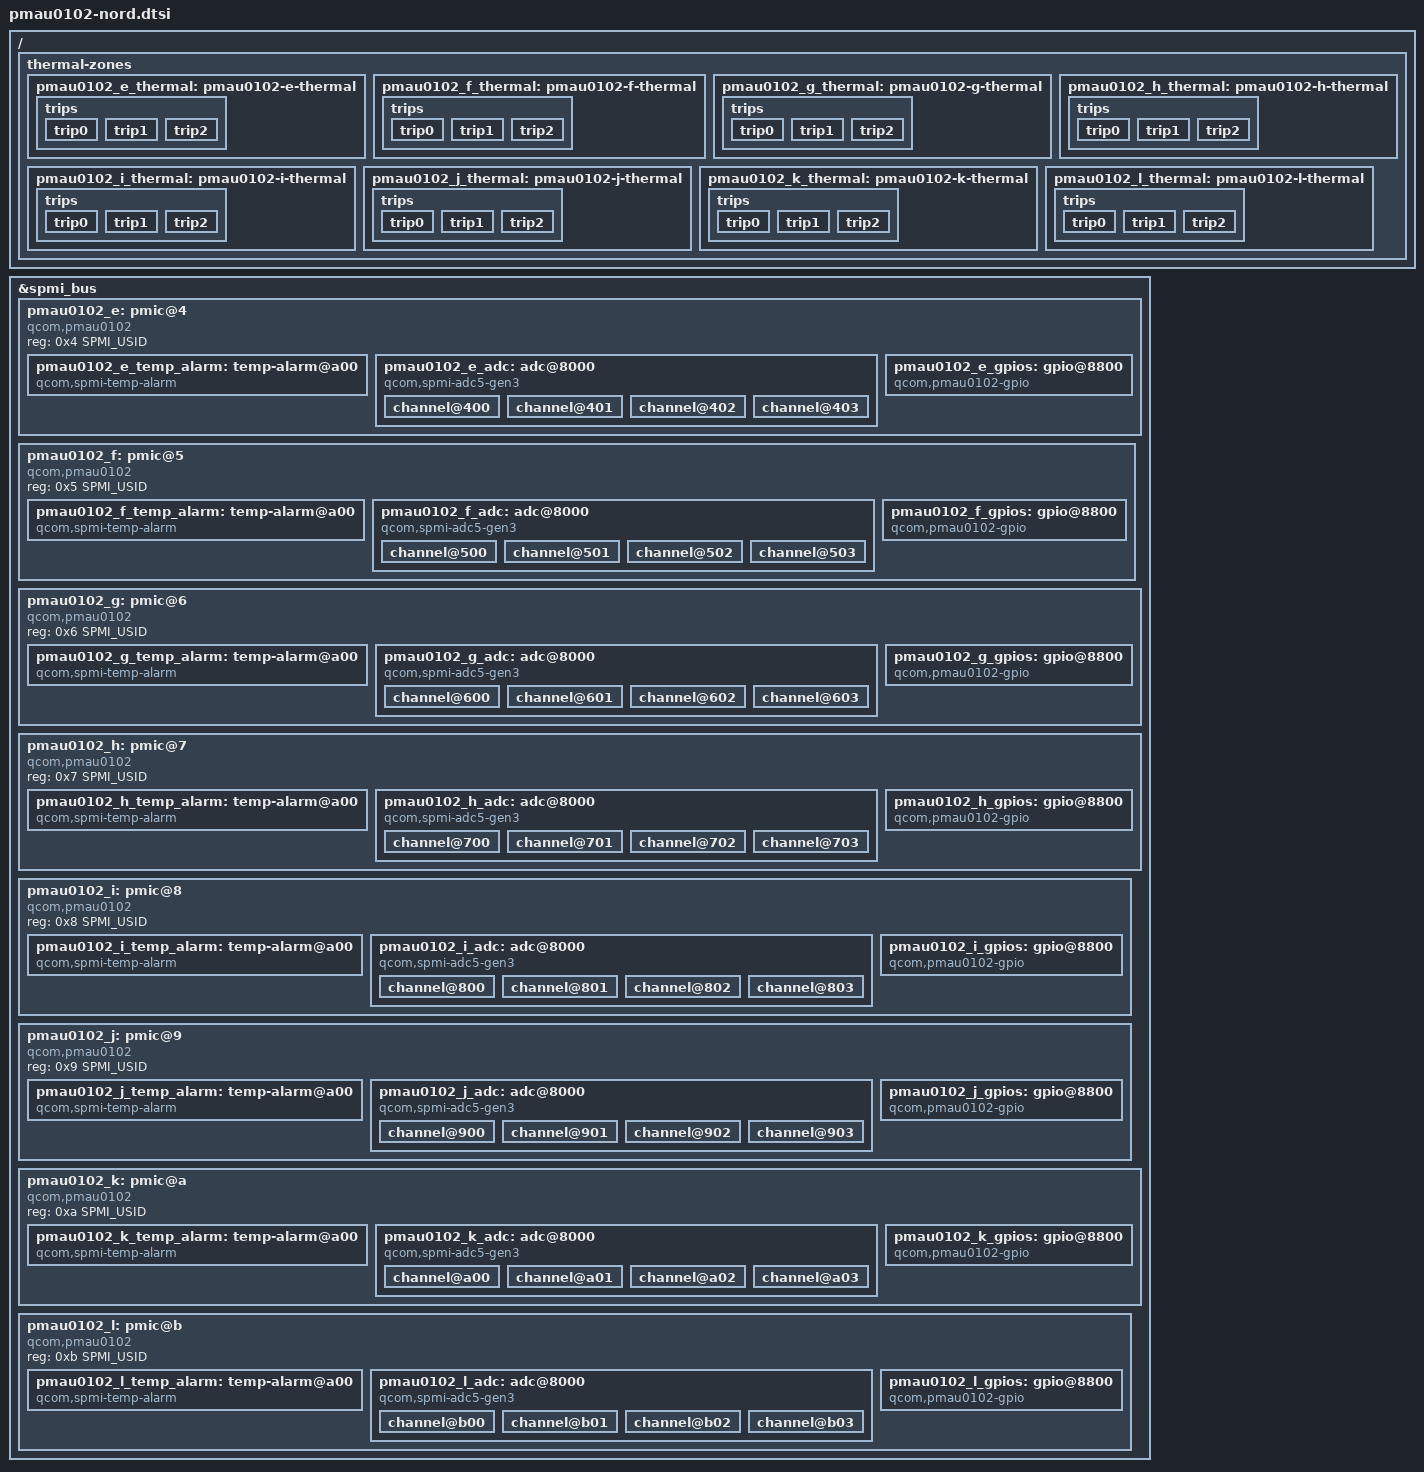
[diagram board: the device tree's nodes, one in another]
// SPDX-License-Identifier: BSD-3-Clause
/*
 * Copyright (c) Qualcomm Technologies, Inc. and/or its subsidiaries.
 */

#include <dt-bindings/interrupt-controller/irq.h>
#include <dt-bindings/spmi/spmi.h>
#include "qcom-adc5-gen3.h"

&spmi_bus {
	pmau0102_e: pmic@4 {
		compatible = "qcom,pmau0102", "qcom,spmi-pmic";
		reg = <0x4 SPMI_USID>;
		#address-cells = <1>;
		#size-cells = <0>;

		pmau0102_e_temp_alarm: temp-alarm@a00 {
			compatible = "qcom,spmi-temp-alarm";
			reg = <0xa00>;
			interrupts = <0x4 0xa 0x0 IRQ_TYPE_EDGE_BOTH>;
			#thermal-sensor-cells = <0>;
		};

		pmau0102_e_adc: adc@8000 {
			compatible = "qcom,spmi-adc5-gen3";
			reg = <0x8000>;
			#address-cells = <1>;
			#size-cells = <0>;
			interrupts = <0x4 0x80 0x1 IRQ_TYPE_EDGE_RISING>;
			#io-channel-cells = <1>;

			channel@400 {
				reg = <ADC5_GEN3_REF_GND(4)>;
				label = "pmau0102_e_ref_gnd";
				qcom,pre-scaling = <1 1>;
			};

			channel@401 {
				reg = <ADC5_GEN3_1P25VREF(4)>;
				label = "pmau0102_e_vref_1p25";
				qcom,pre-scaling = <1 1>;
			};

			channel@402 {
				reg = <ADC5_GEN3_VREF_VADC(4)>;
				label = "pmau0102_e_vref_vadc";
				qcom,pre-scaling = <1 1>;
			};

			channel@403 {
				reg = <ADC5_GEN3_DIE_TEMP(4)>;
				label = "pmau0102_e_die_temp";
				qcom,pre-scaling = <1 1>;
			};
		};

		pmau0102_e_gpios: gpio@8800 {
			compatible = "qcom,pmau0102-gpio", "qcom,spmi-gpio";
			reg = <0x8800>;
			gpio-controller;
			gpio-ranges = <&pmau0102_e_gpios 0 0 12>;
			#gpio-cells = <2>;
			interrupt-controller;
			#interrupt-cells = <2>;
		};
	};

	pmau0102_f: pmic@5 {
		compatible = "qcom,pmau0102", "qcom,spmi-pmic";
		reg = <0x5 SPMI_USID>;
		#address-cells = <1>;
		#size-cells = <0>;

		pmau0102_f_temp_alarm: temp-alarm@a00 {
			compatible = "qcom,spmi-temp-alarm";
			reg = <0xa00>;
			interrupts = <0x5 0xa 0x0 IRQ_TYPE_EDGE_BOTH>;
			#thermal-sensor-cells = <0>;
		};

		pmau0102_f_adc: adc@8000 {
			compatible = "qcom,spmi-adc5-gen3";
			reg = <0x8000>;
			#address-cells = <1>;
			#size-cells = <0>;
			interrupts = <0x5 0x80 0x1 IRQ_TYPE_EDGE_RISING>;
			#io-channel-cells = <1>;

			channel@500 {
				reg = <ADC5_GEN3_REF_GND(5)>;
				label = "pmau0102_f_ref_gnd";
				qcom,pre-scaling = <1 1>;
			};

			channel@501 {
				reg = <ADC5_GEN3_1P25VREF(5)>;
				label = "pmau0102_f_vref_1p25";
				qcom,pre-scaling = <1 1>;
			};

			channel@502 {
				reg = <ADC5_GEN3_VREF_VADC(5)>;
				label = "pmau0102_f_vref_vadc";
				qcom,pre-scaling = <1 1>;
			};

			channel@503 {
				reg = <ADC5_GEN3_DIE_TEMP(5)>;
				label = "pmau0102_f_die_temp";
				qcom,pre-scaling = <1 1>;
			};
		};

		pmau0102_f_gpios: gpio@8800 {
			compatible = "qcom,pmau0102-gpio", "qcom,spmi-gpio";
			reg = <0x8800>;
			gpio-controller;
			gpio-ranges = <&pmau0102_f_gpios 0 0 12>;
			#gpio-cells = <2>;
			interrupt-controller;
			#interrupt-cells = <2>;
		};
	};

	pmau0102_g: pmic@6 {
		compatible = "qcom,pmau0102", "qcom,spmi-pmic";
		reg = <0x6 SPMI_USID>;
		#address-cells = <1>;
		#size-cells = <0>;

		pmau0102_g_temp_alarm: temp-alarm@a00 {
			compatible = "qcom,spmi-temp-alarm";
			reg = <0xa00>;
			interrupts = <0x6 0xa 0x0 IRQ_TYPE_EDGE_BOTH>;
			#thermal-sensor-cells = <0>;
		};

		pmau0102_g_adc: adc@8000 {
			compatible = "qcom,spmi-adc5-gen3";
			reg = <0x8000>;
			#address-cells = <1>;
			#size-cells = <0>;
			interrupts = <0x6 0x80 0x1 IRQ_TYPE_EDGE_RISING>;
			#io-channel-cells = <1>;

			channel@600 {
				reg = <ADC5_GEN3_REF_GND(6)>;
				label = "pmau0102_g_ref_gnd";
				qcom,pre-scaling = <1 1>;
			};

			channel@601 {
				reg = <ADC5_GEN3_1P25VREF(6)>;
				label = "pmau0102_g_vref_1p25";
				qcom,pre-scaling = <1 1>;
			};

			channel@602 {
				reg = <ADC5_GEN3_VREF_VADC(6)>;
				label = "pmau0102_g_vref_vadc";
				qcom,pre-scaling = <1 1>;
			};

			channel@603 {
				reg = <ADC5_GEN3_DIE_TEMP(6)>;
				label = "pmau0102_g_die_temp";
				qcom,pre-scaling = <1 1>;
			};
		};

		pmau0102_g_gpios: gpio@8800 {
			compatible = "qcom,pmau0102-gpio", "qcom,spmi-gpio";
			reg = <0x8800>;
			gpio-controller;
			gpio-ranges = <&pmau0102_g_gpios 0 0 12>;
			#gpio-cells = <2>;
			interrupt-controller;
			#interrupt-cells = <2>;
		};
	};

	pmau0102_h: pmic@7 {
		compatible = "qcom,pmau0102", "qcom,spmi-pmic";
		reg = <0x7 SPMI_USID>;
		#address-cells = <1>;
		#size-cells = <0>;

		pmau0102_h_temp_alarm: temp-alarm@a00 {
			compatible = "qcom,spmi-temp-alarm";
			reg = <0xa00>;
			interrupts = <0x7 0xa 0x0 IRQ_TYPE_EDGE_BOTH>;
			#thermal-sensor-cells = <0>;
		};

		pmau0102_h_adc: adc@8000 {
			compatible = "qcom,spmi-adc5-gen3";
			reg = <0x8000>;
			#address-cells = <1>;
			#size-cells = <0>;
			interrupts = <0x7 0x80 0x1 IRQ_TYPE_EDGE_RISING>;
			#io-channel-cells = <1>;

			channel@700 {
				reg = <ADC5_GEN3_REF_GND(7)>;
				label = "pmau0102_h_ref_gnd";
				qcom,pre-scaling = <1 1>;
			};

			channel@701 {
				reg = <ADC5_GEN3_1P25VREF(7)>;
				label = "pmau0102_h_vref_1p25";
				qcom,pre-scaling = <1 1>;
			};

			channel@702 {
				reg = <ADC5_GEN3_VREF_VADC(7)>;
				label = "pmau0102_h_vref_vadc";
				qcom,pre-scaling = <1 1>;
			};

			channel@703 {
				reg = <ADC5_GEN3_DIE_TEMP(7)>;
				label = "pmau0102_h_die_temp";
				qcom,pre-scaling = <1 1>;
			};
		};

		pmau0102_h_gpios: gpio@8800 {
			compatible = "qcom,pmau0102-gpio", "qcom,spmi-gpio";
			reg = <0x8800>;
			gpio-controller;
			gpio-ranges = <&pmau0102_h_gpios 0 0 12>;
			#gpio-cells = <2>;
			interrupt-controller;
			#interrupt-cells = <2>;
		};
	};

	pmau0102_i: pmic@8 {
		compatible = "qcom,pmau0102", "qcom,spmi-pmic";
		reg = <0x8 SPMI_USID>;
		#address-cells = <1>;
		#size-cells = <0>;

		pmau0102_i_temp_alarm: temp-alarm@a00 {
			compatible = "qcom,spmi-temp-alarm";
			reg = <0xa00>;
			interrupts = <0x8 0xa 0x0 IRQ_TYPE_EDGE_BOTH>;
			#thermal-sensor-cells = <0>;
		};

		pmau0102_i_adc: adc@8000 {
			compatible = "qcom,spmi-adc5-gen3";
			reg = <0x8000>;
			#address-cells = <1>;
			#size-cells = <0>;
			interrupts = <0x8 0x80 0x1 IRQ_TYPE_EDGE_RISING>;
			#io-channel-cells = <1>;

			channel@800 {
				reg = <ADC5_GEN3_REF_GND(8)>;
				label = "pmau0102_i_ref_gnd";
				qcom,pre-scaling = <1 1>;
			};

			channel@801 {
				reg = <ADC5_GEN3_1P25VREF(8)>;
				label = "pmau0102_i_vref_1p25";
				qcom,pre-scaling = <1 1>;
			};

			channel@802 {
				reg = <ADC5_GEN3_VREF_VADC(8)>;
				label = "pmau0102_i_vref_vadc";
				qcom,pre-scaling = <1 1>;
			};

			channel@803 {
				reg = <ADC5_GEN3_DIE_TEMP(8)>;
				label = "pmau0102_i_die_temp";
				qcom,pre-scaling = <1 1>;
			};
		};

		pmau0102_i_gpios: gpio@8800 {
			compatible = "qcom,pmau0102-gpio", "qcom,spmi-gpio";
			reg = <0x8800>;
			gpio-controller;
			gpio-ranges = <&pmau0102_i_gpios 0 0 12>;
			#gpio-cells = <2>;
			interrupt-controller;
			#interrupt-cells = <2>;
		};
	};

	pmau0102_j: pmic@9 {
		compatible = "qcom,pmau0102", "qcom,spmi-pmic";
		reg = <0x9 SPMI_USID>;
		#address-cells = <1>;
		#size-cells = <0>;

		pmau0102_j_temp_alarm: temp-alarm@a00 {
			compatible = "qcom,spmi-temp-alarm";
			reg = <0xa00>;
			interrupts = <0x9 0xa 0x0 IRQ_TYPE_EDGE_BOTH>;
			#thermal-sensor-cells = <0>;
		};

		pmau0102_j_adc: adc@8000 {
			compatible = "qcom,spmi-adc5-gen3";
			reg = <0x8000>;
			#address-cells = <1>;
			#size-cells = <0>;
			interrupts = <0x9 0x80 0x1 IRQ_TYPE_EDGE_RISING>;
			#io-channel-cells = <1>;

			channel@900 {
				reg = <ADC5_GEN3_REF_GND(9)>;
				label = "pmau0102_j_ref_gnd";
				qcom,pre-scaling = <1 1>;
			};

			channel@901 {
				reg = <ADC5_GEN3_1P25VREF(9)>;
				label = "pmau0102_j_vref_1p25";
				qcom,pre-scaling = <1 1>;
			};

			channel@902 {
				reg = <ADC5_GEN3_VREF_VADC(9)>;
				label = "pmau0102_j_vref_vadc";
				qcom,pre-scaling = <1 1>;
			};

			channel@903 {
				reg = <ADC5_GEN3_DIE_TEMP(9)>;
				label = "pmau0102_j_die_temp";
				qcom,pre-scaling = <1 1>;
			};
		};

		pmau0102_j_gpios: gpio@8800 {
			compatible = "qcom,pmau0102-gpio", "qcom,spmi-gpio";
			reg = <0x8800>;
			gpio-controller;
			gpio-ranges = <&pmau0102_j_gpios 0 0 12>;
			#gpio-cells = <2>;
			interrupt-controller;
			#interrupt-cells = <2>;
		};
	};

	pmau0102_k: pmic@a {
		compatible = "qcom,pmau0102", "qcom,spmi-pmic";
		reg = <0xa SPMI_USID>;
		#address-cells = <1>;
		#size-cells = <0>;

		pmau0102_k_temp_alarm: temp-alarm@a00 {
			compatible = "qcom,spmi-temp-alarm";
			reg = <0xa00>;
			interrupts = <0xa 0xa 0x0 IRQ_TYPE_EDGE_BOTH>;
			#thermal-sensor-cells = <0>;
		};

		pmau0102_k_adc: adc@8000 {
			compatible = "qcom,spmi-adc5-gen3";
			reg = <0x8000>;
			#address-cells = <1>;
			#size-cells = <0>;
			interrupts = <0xa 0x80 0x1 IRQ_TYPE_EDGE_RISING>;
			#io-channel-cells = <1>;

			channel@a00 {
				reg = <ADC5_GEN3_REF_GND(0xa)>;
				label = "pmau0102_k_ref_gnd";
				qcom,pre-scaling = <1 1>;
			};

			channel@a01 {
				reg = <ADC5_GEN3_1P25VREF(0xa)>;
				label = "pmau0102_k_vref_1p25";
				qcom,pre-scaling = <1 1>;
			};

			channel@a02 {
				reg = <ADC5_GEN3_VREF_VADC(0xa)>;
				label = "pmau0102_k_vref_vadc";
				qcom,pre-scaling = <1 1>;
			};

			channel@a03 {
				reg = <ADC5_GEN3_DIE_TEMP(0xa)>;
				label = "pmau0102_k_die_temp";
				qcom,pre-scaling = <1 1>;
			};
		};

		pmau0102_k_gpios: gpio@8800 {
			compatible = "qcom,pmau0102-gpio", "qcom,spmi-gpio";
			reg = <0x8800>;
			gpio-controller;
			gpio-ranges = <&pmau0102_k_gpios 0 0 12>;
			#gpio-cells = <2>;
			interrupt-controller;
			#interrupt-cells = <2>;
		};
	};

	pmau0102_l: pmic@b {
		compatible = "qcom,pmau0102", "qcom,spmi-pmic";
		reg = <0xb SPMI_USID>;
		#address-cells = <1>;
		#size-cells = <0>;

		pmau0102_l_temp_alarm: temp-alarm@a00 {
			compatible = "qcom,spmi-temp-alarm";
			reg = <0xa00>;
			interrupts = <0xb 0xa 0x0 IRQ_TYPE_EDGE_BOTH>;
			#thermal-sensor-cells = <0>;
		};

		pmau0102_l_adc: adc@8000 {
			compatible = "qcom,spmi-adc5-gen3";
			reg = <0x8000>;
			#address-cells = <1>;
			#size-cells = <0>;
			interrupts = <0xb 0x80 0x1 IRQ_TYPE_EDGE_RISING>;
			#io-channel-cells = <1>;

			channel@b00 {
				reg = <ADC5_GEN3_REF_GND(0xb)>;
				label = "pmau0102_l_ref_gnd";
				qcom,pre-scaling = <1 1>;
			};

			channel@b01 {
				reg = <ADC5_GEN3_1P25VREF(0xb)>;
				label = "pmau0102_l_vref_1p25";
				qcom,pre-scaling = <1 1>;
			};

			channel@b02 {
				reg = <ADC5_GEN3_VREF_VADC(0xb)>;
				label = "pmau0102_l_vref_vadc";
				qcom,pre-scaling = <1 1>;
			};

			channel@b03 {
				reg = <ADC5_GEN3_DIE_TEMP(0xb)>;
				label = "pmau0102_l_die_temp";
				qcom,pre-scaling = <1 1>;
			};
		};

		pmau0102_l_gpios: gpio@8800 {
			compatible = "qcom,pmau0102-gpio", "qcom,spmi-gpio";
			reg = <0x8800>;
			gpio-controller;
			gpio-ranges = <&pmau0102_l_gpios 0 0 12>;
			#gpio-cells = <2>;
			interrupt-controller;
			#interrupt-cells = <2>;
		};
	};
};

/ {
	thermal-zones {
		pmau0102_e_thermal: pmau0102-e-thermal {
			polling-delay-passive = <100>;
			thermal-sensors = <&pmau0102_e_temp_alarm>;
			trips {
				trip0 { temperature = <95000>; hysteresis = <0>; type = "passive"; };
				trip1 { temperature = <115000>; hysteresis = <0>; type = "hot"; };
				trip2 { temperature = <145000>; hysteresis = <0>; type = "critical"; };
			};
		};

		pmau0102_f_thermal: pmau0102-f-thermal {
			polling-delay-passive = <100>;
			thermal-sensors = <&pmau0102_f_temp_alarm>;
			trips {
				trip0 { temperature = <95000>; hysteresis = <0>; type = "passive"; };
				trip1 { temperature = <115000>; hysteresis = <0>; type = "hot"; };
				trip2 { temperature = <145000>; hysteresis = <0>; type = "critical"; };
			};
		};

		pmau0102_g_thermal: pmau0102-g-thermal {
			polling-delay-passive = <100>;
			thermal-sensors = <&pmau0102_g_temp_alarm>;
			trips {
				trip0 { temperature = <95000>; hysteresis = <0>; type = "passive"; };
				trip1 { temperature = <115000>; hysteresis = <0>; type = "hot"; };
				trip2 { temperature = <145000>; hysteresis = <0>; type = "critical"; };
			};
		};

		pmau0102_h_thermal: pmau0102-h-thermal {
			polling-delay-passive = <100>;
			thermal-sensors = <&pmau0102_h_temp_alarm>;
			trips {
				trip0 { temperature = <95000>; hysteresis = <0>; type = "passive"; };
				trip1 { temperature = <115000>; hysteresis = <0>; type = "hot"; };
				trip2 { temperature = <145000>; hysteresis = <0>; type = "critical"; };
			};
		};

		pmau0102_i_thermal: pmau0102-i-thermal {
			polling-delay-passive = <100>;
			thermal-sensors = <&pmau0102_i_temp_alarm>;
			trips {
				trip0 { temperature = <95000>; hysteresis = <0>; type = "passive"; };
				trip1 { temperature = <115000>; hysteresis = <0>; type = "hot"; };
				trip2 { temperature = <145000>; hysteresis = <0>; type = "critical"; };
			};
		};

		pmau0102_j_thermal: pmau0102-j-thermal {
			polling-delay-passive = <100>;
			thermal-sensors = <&pmau0102_j_temp_alarm>;
			trips {
				trip0 { temperature = <95000>; hysteresis = <0>; type = "passive"; };
				trip1 { temperature = <115000>; hysteresis = <0>; type = "hot"; };
				trip2 { temperature = <145000>; hysteresis = <0>; type = "critical"; };
			};
		};

		pmau0102_k_thermal: pmau0102-k-thermal {
			polling-delay-passive = <100>;
			thermal-sensors = <&pmau0102_k_temp_alarm>;
			trips {
				trip0 { temperature = <95000>; hysteresis = <0>; type = "passive"; };
				trip1 { temperature = <115000>; hysteresis = <0>; type = "hot"; };
				trip2 { temperature = <145000>; hysteresis = <0>; type = "critical"; };
			};
		};

		pmau0102_l_thermal: pmau0102-l-thermal {
			polling-delay-passive = <100>;
			thermal-sensors = <&pmau0102_l_temp_alarm>;
			trips {
				trip0 { temperature = <95000>; hysteresis = <0>; type = "passive"; };
				trip1 { temperature = <115000>; hysteresis = <0>; type = "hot"; };
				trip2 { temperature = <145000>; hysteresis = <0>; type = "critical"; };
			};
		};
	};
};
